VERSION ""

NS_ :

	ENVs_

BS_:

BU_: OVMS BMS ESP Gateway BCM ChargeCtrl ClimaECU Instruments AmbientSensor GearModule Powertrain Motor

// ---------------------------------------------------------------------------
// KCAN (500 kbps) — convenience/comfort bus, accessible via J533 harness
// OVMS: CAN bus 3 (m_can3).  Most metric data lives here.
// ---------------------------------------------------------------------------

BO_ 253 ESP_Speed: 8 ESP
 SG_ Speed : 32|16@1+ (0.01,0) [0|655.35] "km/h" OVMS

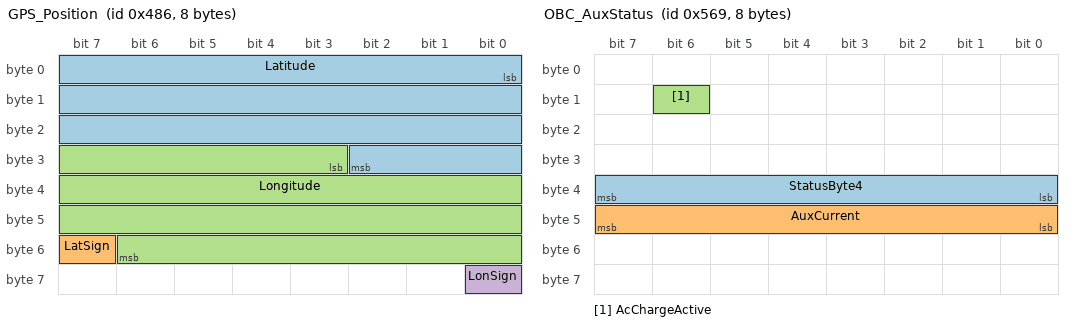
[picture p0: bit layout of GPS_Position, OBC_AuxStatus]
BO_ 1158 GPS_Position: 8 Gateway
 SG_ Latitude : 0|27@1+ (1e-006,0) [0|90] "deg" OVMS
 SG_ LatSign : 55|1@1+ (1,0) [0|1] "" OVMS
 SG_ Longitude : 27|28@1+ (1e-006,0) [0|180] "deg" OVMS
 SG_ LonSign : 56|1@1+ (1,0) [0|1] "" OVMS

BO_ 1385 OBC_AuxStatus: 8 OBC
 SG_ StatusByte4 : 32|8@1+ (1,0) [0|255] ""  Vector__XXX
 SG_ AuxCurrent  : 40|8@1+ (1,0) [0|255] "A" Vector__XXX
 SG_ AcChargeActive : 14|1@1+ (1,0) [0|1] "" Vector__XXX

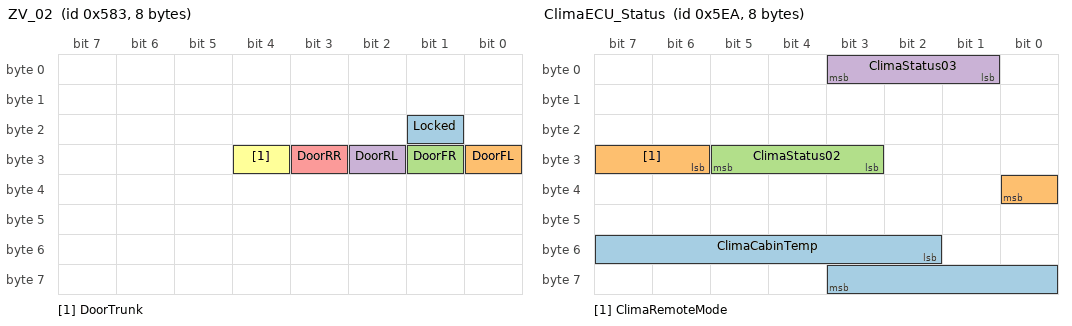
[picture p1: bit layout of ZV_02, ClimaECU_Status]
BO_ 1411 ZV_02: 8 BCM
 SG_ Locked : 17|1@1+ (1,0) [0|1] "" OVMS
 SG_ DoorFL : 24|1@1+ (1,0) [0|1] "" OVMS
 SG_ DoorFR : 25|1@1+ (1,0) [0|1] "" OVMS
 SG_ DoorRL : 26|1@1+ (1,0) [0|1] "" OVMS
 SG_ DoorRR : 27|1@1+ (1,0) [0|1] "" OVMS
 SG_ DoorTrunk : 28|1@1+ (1,0) [0|1] "" OVMS

BO_ 1428 ChargeManagement: 8 ChargeCtrl
 SG_ ChargeDurationFull : 12|9@1+ (5,0) [0|2555] "min" OVMS
 SG_ ChargeTimerMode : 21|2@1+ (1,0) [0|3] "" OVMS
 SG_ ChargeInProgress : 29|1@1+ (1,0) [0|1] "" OVMS
 SG_ ChargeType : 42|2@1+ (1,0) [0|3] "" OVMS
 SG_ ChargePort : 42|2@1+ (1,0) [0|3] "" OVMS
 SG_ CabinSetpoint : 56|5@1+ (0.5,15.5) [15.5|31.5] "degC" OVMS

BO_ 1438 BMS_BatTemp: 8 BMS
 SG_ BatTemp : 16|8@1+ (0.5,-40) [-40|87.5] "degC" OVMS

BO_ 1482 BMS_BatEnergyRemaining: 8 BMS
 SG_ BatEnergyRemaining : 12|11@1+ (0.05,0) [0|102.35] "kWh" OVMS

BO_ 1514 ClimaECU_Status: 8 ClimaECU
 SG_ ClimaCabinTemp : 50|10@1+ (0.1,-40) [-40|62.3] "degC" OVMS
 SG_ ClimaRemoteMode : 30|3@1+ (1,0) [0|7] "" OVMS
 SG_ ClimaStatus02 : 27|3@1+ (1,0) [0|7] "" OVMS
 SG_ ClimaStatus03 : 1|3@1+ (1,0) [0|7] "" OVMS

BO_ 949 ClimaRunning_3B5: 8 ClimaECU
 SG_ ClimaRunning : 7|1@1+ (1,0) [0|1] "" OVMS

BO_ 1516 ClimaStatus_5EC: 8 ClimaECU
 SG_ ClimaStatus : 40|8@1+ (1,0) [0|255] "" OVMS

BO_ 1525 Instruments_Range: 8 Instruments
 SG_ RangeEst : 29|11@1+ (1,0) [0|2047] "km" OVMS
 SG_ RangeIdeal : 0|11@1+ (1,0) [0|2047] "km" OVMS

BO_ 1626 BCM_01: 8 BCM
 SG_ HoodOpen : 32|1@1+ (1,0) [0|1] "" OVMS

BO_ 1646 InnenTemp: 8 BCM
 SG_ CabinTemp : 32|8@1+ (0.5,-50) [-50|77] "degC" OVMS
 SG_ ClimaRunning : 17|1@1+ (1,0) [0|1] "" OVMS

BO_ 1712 FS_Temp: 8 AmbientSensor
 SG_ FsTemp : 32|8@1+ (0.5,-40) [-40|87.5] "degC" OVMS

BO_ 1717 AmbientTemp: 8 AmbientSensor
 SG_ AirTemp : 16|10@1+ (0.1,-40) [-40|62.3] "degC" OVMS
 SG_ SolarTemp : 48|11@1+ (0.1,-40) [-40|164.7] "degC" OVMS

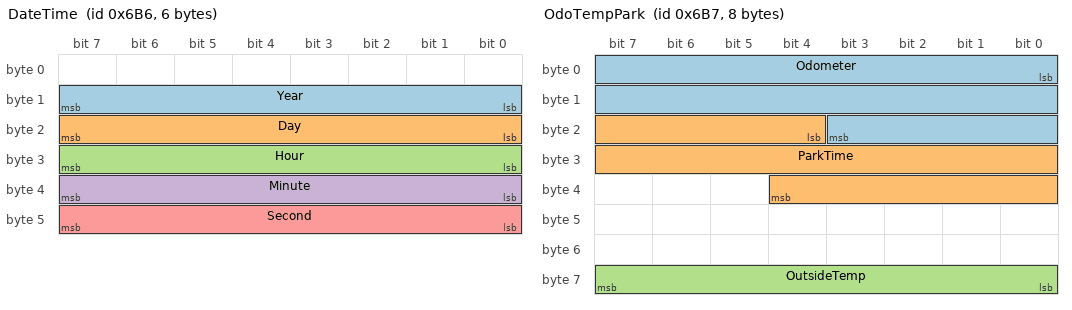
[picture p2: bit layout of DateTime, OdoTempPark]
BO_ 1718 DateTime: 6 Gateway
 SG_ Year : 8|8@1+ (1,0) [0|99] "" OVMS
 SG_ Day : 16|8@1+ (1,0) [1|31] "" OVMS
 SG_ Hour : 24|8@1+ (1,0) [0|23] "" OVMS
 SG_ Minute : 32|8@1+ (1,0) [0|59] "" OVMS
 SG_ Second : 40|8@1+ (1,0) [0|59] "" OVMS

BO_ 1719 OdoTempPark: 8 Gateway
 SG_ Odometer : 0|20@1+ (1,0) [0|1048575] "km" OVMS
 SG_ ParkTime : 20|17@1+ (1,0) [0|131071] "s" OVMS
 SG_ OutsideTemp : 56|8@1+ (0.5,-50) [-50|77] "degC" OVMS

// OVMS transmits this frame on KCAN as the OCU application-level presence frame.
// Must be sent at ~5 Hz while active. Action bits are set for one tick then cleared.
// Note: this is NOT the OSEK NM alive — see 0x1B00007D below for OVMS's NM alive
// (0x1B000067 is a foreign ECU's node, not ours — see comment there).
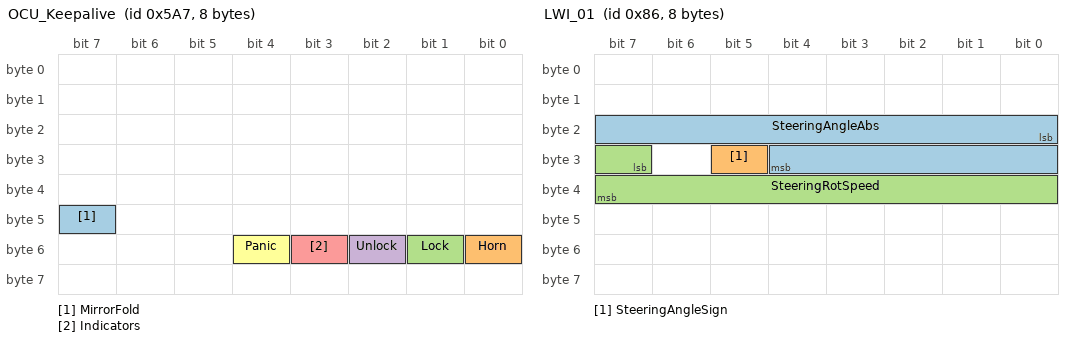
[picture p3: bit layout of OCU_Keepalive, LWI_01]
BO_ 1447 OCU_Keepalive: 8 OVMS
 SG_ MirrorFold : 47|1@1+ (1,0) [0|1] "" Vector__XXX
 SG_ Horn : 48|1@1+ (1,0) [0|1] "" Vector__XXX
 SG_ Lock : 49|1@1+ (1,0) [0|1] "" Vector__XXX
 SG_ Unlock : 50|1@1+ (1,0) [0|1] "" Vector__XXX
 SG_ Indicators : 51|1@1+ (1,0) [0|1] "" Vector__XXX
 SG_ Panic : 52|1@1+ (1,0) [0|1] "" Vector__XXX

// ---------------------------------------------------------------------------
// FCAN (500 kbps) — powertrain bus, accessible via J533 harness
// OVMS: CAN bus 2 (m_can2).  BMS (SoC, HV bus, trip energy), gear selector, VIN.
// ---------------------------------------------------------------------------

BO_ 305 BMS_SoC: 8 BMS
 SG_ SoC : 24|8@1+ (0.5,0) [0|127.5] "%" OVMS

BO_ 401 BMS_PowerBus: 8 BMS
 SG_ BatCurrent : 12|12@1+ (1,-2047) [-2047|2048] "A" OVMS
 SG_ BatVoltage : 24|12@1+ (0.25,0) [0|1023.75] "V" OVMS

BO_ 687 BMS_TripEnergy: 8 BMS
 SG_ NetEnergy : 16|16@1+ (1,0) [0|65535] "mWh" OVMS

BO_ 391 GearSelector: 8 GearModule
 SG_ GearPosition : 16|4@1+ (1,0) [0|15] "" OVMS

// VIN is spread across three sequential frames (frame index 0, 1, 2 in d[0]).
// Not representable as a simple signal; assembled in firmware from all three.
BO_ 1716 VIN_Broadcast: 8 Gateway
 SG_ VIN_FrameIndex : 0|8@1+ (1,0) [0|2] "" OVMS

// Clamp/terminal status (0x3C0). d[2] carries the terminal bits: KL_S (accessory)
// and KL_15 (ignition). KL_15 = car awake / switched on by the user -> ms_v_env_awake.
BO_ 960 ClampStatus: 8 Gateway
 SG_ KlS_Accessory : 16|1@1+ (1,0) [0|1] "" OVMS
 SG_ Kl15_Ignition : 17|1@1+ (1,0) [0|1] "" OVMS

// OBD_01 (0x391). d[7] bit 5 = OBD_Driving_Cycle: the drivetrain READY flag, set only
// when the car is drivable. ms_v_env_on = KL_15 && READY. d[5] = accelerator pedal.
BO_ 913 OBD_01: 8 Powertrain
 SG_ OBD_Driving_Cycle : 61|1@1+ (1,0) [0|1] "" OVMS
 SG_ OBD_Abs_Pedal_Pos : 40|8@1+ (0.392,0) [0|100] "%" OVMS

// ---------------------------------------------------------------------------
// FCAN decode candidates and partially decoded frames.
// Originally observed in can2-3.3.005-800-gc60d79ed-dirty_ota_1_edge-20260412-175611
// (CCS charging, ignition off). Per-frame comments record progress as stimulation
// captures land. As of Capture 17 (D + B short drive): 0x0B2 fully decoded as
// wheel speeds; 0x057 byte 3 and 0x0B4 bytes 3/6 partially decoded.
// ---------------------------------------------------------------------------

BO_ 87 Unknown_057: 4 Vector__XXX
 SG_ MotorTorqueRequest : 24|8@1+ (1,0) [0|255] "" OVMS
BO_ 134 LWI_01: 8 Gateway
 SG_ SteeringAngleAbs : 16|13@1+ (0.1,0) [0|800] "deg" OVMS
 SG_ SteeringAngleSign : 29|1@1+ (1,0) [0|1] "" OVMS
 SG_ SteeringRotSpeed : 31|9@1+ (5,0) [0|2500] "deg/s" OVMS
BO_ 167 Motor_11: 8 Motor
BO_ 168 Motor_12: 8 Motor
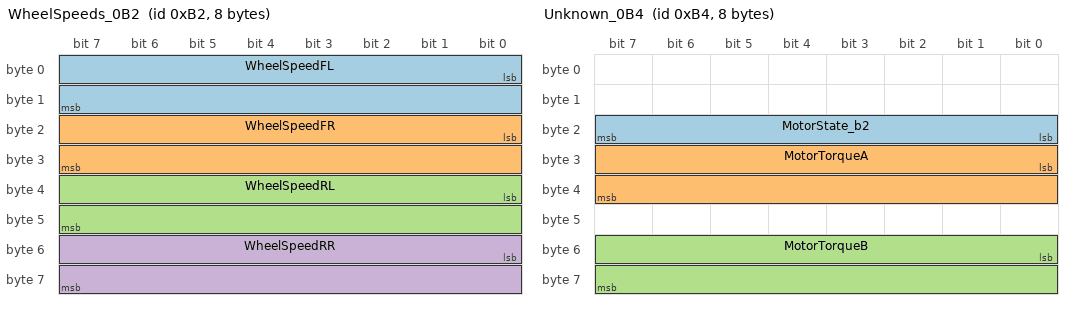
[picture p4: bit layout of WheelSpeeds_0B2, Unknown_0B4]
BO_ 178 WheelSpeeds_0B2: 8 ESP
 SG_ WheelSpeedFL : 0|16@1+ (0.0078125,0) [0|511.99] "km/h" OVMS
 SG_ WheelSpeedFR : 16|16@1+ (0.0078125,0) [0|511.99] "km/h" OVMS
 SG_ WheelSpeedRL : 32|16@1+ (0.0078125,0) [0|511.99] "km/h" OVMS
 SG_ WheelSpeedRR : 48|16@1+ (0.0078125,0) [0|511.99] "km/h" OVMS
BO_ 179 Unknown_0B3: 8 Vector__XXX
BO_ 180 Unknown_0B4: 8 Vector__XXX
 SG_ MotorState_b2 : 16|8@1+ (1,0) [0|255] "" OVMS
 SG_ MotorTorqueA : 24|16@1+ (1,0) [0|65535] "" OVMS
 SG_ MotorTorqueB : 48|16@1+ (1,0) [0|65535] "" OVMS
BO_ 263 Motor_04: 8 Motor
BO_ 288 TSK_06: 8 Motor
BO_ 289 Motor_20: 8 Motor
BO_ 869 BrakePedal_365: 8 Vector__XXX
 SG_ BrakeActive : 32|1@1+ (1,0) [0|1] "" OVMS
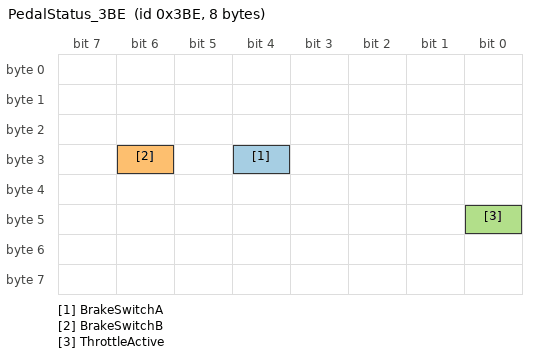
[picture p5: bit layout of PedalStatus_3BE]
BO_ 958 PedalStatus_3BE: 8 Vector__XXX
 SG_ BrakeSwitchA : 28|1@1+ (1,0) [0|1] "" OVMS
 SG_ BrakeSwitchB : 30|1@1+ (1,0) [0|1] "" OVMS
 SG_ ThrottleActive : 40|1@1+ (1,0) [0|1] "" OVMS

// ---------------------------------------------------------------------------
// OSEK/AUTOSAR NM frames on KCAN (29-bit extended IDs: 0x1B000000 | node_id)
// Each active KCAN node broadcasts its alive frame at ~1 Hz.
//
// Shared 8-byte payload layout, confirmed across 10 nodes (9 real ECUs plus
// OVMS: 0x0C, 0x0E, 0x10, 0x14, 0x46, 0x4A, 0x4B, 0x67, 0xA9, 0x7D) in
// tests/candumps/can3-3.3.006-364-gaefeffec5_ota_0_edge-20260731-112417.crtd
// (14384 frames, 29.3s of bus traffic, RX unless noted). byte0 matches the
// low byte of the CAN ID without exception on every one of the 10 nodes.
//
//   byte0  node id (== CAN ID & 0xFF).
//   byte1  control. Real nodes: 0x00 (92% of frames), 0x10 (8%) — and 0x10 is
//          seen ONLY on node 0x67. CONSISTENT WITH an Active-Wakeup/initiator
//          bit in an AUTOSAR-style NM control bit vector (0x67 is the node
//          this firmware previously impersonated, see BO_ 2600468583 below),
//          but that reading rests on one capture and is not proven against
//          the MQB NM spec.
//   byte2  state. Real nodes: 0x01 (74%), 0x02 (25%), 0x04 (1%). Bus-wide
//          transition observed: nodes 0x0C, 0x14 and 0x0E each flip
//          0x01 -> 0x02 at the same instant (t=+5.33s in the capture above),
//          independently of one another. CONSISTENT WITH Repeat-Message ->
//          Normal-Operation (present in both OSEK NM and AUTOSAR NM) a few
//          seconds after wake — a hypothesis from one 29s capture, NOT
//          settled against the spec.
//   byte3  real nodes: 0x01 (92%) / 0x00 (8%).
//   byte4  real nodes: 0x04 (89%) / 0x0c (11%) / 0x00 (1%). Node 0x0E visits
//          byte2=0x04 with byte4=0x00 together — CONSISTENT WITH a
//          ready-to-sleep state, same one-capture caveat as byte2 above.
//   byte5  real nodes: 0x00 (98%) / 0x08 (2%).
//   byte6  real nodes: 0x00 (82%) / 0x04 (9%) / 0x1e (9%).
//   byte7  0x00 on 100% of real-node frames (invariant).
//
// OVMS (node 0x7D, BO_ 2600468605 below) holds byte2=0x08 and byte4=0x14
// constant across all 30 transmitted frames in the capture and never
// transitions — outside this one capture's real-node byte2/byte4 sets above,
// but NOT unattested corpus-wide: a full-corpus scan (all 42 .crtd, RX only,
// 73510 NM frames, 16 nodes) finds byte2=0x08 as the second most common
// byte2 value (22234 frames, 14 real nodes) and byte4=0x14 directly attested
// (126 frames, nodes 0x0E and 0x10) — both were deliberately chosen in
// WI-NM-1 from that full-corpus scan (see vehicle_vwegolf.h). The open
// question is state-machine participation over time (byte2 is a state field
// that real nodes vary and we hold constant), not value legitimacy.
//
// OVMS must send 0x1B00007D before issuing BAP commands on a freshly-woken bus.
// The clima ECU rejects BAP from nodes not present in the NM ring.
// ---------------------------------------------------------------------------

// 0x1B000067 (extended) — foreign ECU's OSEK NM alive, node 0x67. NOT ours: a
// corpus scan (crtd.py iter_frames, RX only, over all 41 .crtd files in
// tests/candumps/, filtered to id 0x1B0000xx) found 73264 NM frames total across
// 32 of the 41 files; node 0x67 already occupied by a live ECU — 20 of those files
// carry 0x1B000067, 6369 frames at sustained cadence, payload varying
// within a session (67 10 04 01 01 / 67 10 08 01 01 / 67 00 08 01 01 — byte1=0x00
// is never something OVMS emits). The formerly-"confirmed" fixed payload
// 67 10 41 84 14 00 00 00, previously attributed to OVMS, appears zero times in
// that scan — sender attribution below corrected accordingly. See VWEGOLF_NM_NODE_ID
// in vehicle_vwegolf.h.
BO_ 2600468583 NM_Unknown67_Alive: 8 Vector__XXX
 SG_ NM_NodeId : 0|8@1+ (1,0) [0|255] "" Vector__XXX
 SG_ NM_Control : 8|8@1+ (1,0) [0|255] "" Vector__XXX

// 0x1B00007D (extended) — OVMS OSEK NM alive (node 0x7D = OVMS).
// Sent by CommandWakeup() and SendNmAlive() on/after a freshly-woken bus, before
// issuing BAP commands. 0x7D is unobserved across all 73264 scanned NM frames —
// chosen because it is unclaimed IN THE CAPTURES, not because the slot is confirmed
// free on the vehicle. Payload 7D 10 08 01 14 00 00 00: byte2/byte3 mirror the
// single-bit PNC-request pattern node 0x46 (Climatronic) puts on the wire.
// can3-3.3.006-364-gaefeffec5_ota_0_edge-20260731-112417.crtd corroborates
// byte1=0x10 as an Active-Wakeup/initiator-style control bit (see the shared
// payload layout comment above) — one capture, not proven. OSEK-vs-AUTOSAR
// identification of the NM variant itself remains unsettled against the MQB
// NM spec.
// See VWEGOLF_NM_PAYLOAD in vehicle_vwegolf.h.
BO_ 2600468605 NM_OVMS_Alive: 8 OVMS
 SG_ NM_NodeId : 0|8@1+ (1,0) [0|255] "" Vector__XXX
 SG_ NM_Control : 8|8@1+ (1,0) [0|255] "" Vector__XXX

// 0x1B000025 (extended) — ClimaECU OSEK NM alive (node 0x25), expected by
// protocol convention (mirrors the node-claim pattern of 0x1B000067/0x1B00007D
// above) — NOT confirmed on the wire. Zero occurrences across all 42 .crtd
// files in the corpus (RX and TX). See CM_ below for the full node-observation
// breakdown.
BO_ 2600468517 NM_ClimaECU_Alive: 8 ClimaECU
 SG_ NM_NodeId : 0|8@1+ (1,0) [0|255] "" Vector__XXX
 SG_ NM_Control : 8|8@1+ (1,0) [0|255] "" Vector__XXX

// 0x17330301 (extended) — dominant-bit wake frame sent by CommandWakeup().
// TX_Fail is expected (nodes sleeping, no ACK). Dominant bits wake transceivers.
// Data: 40 00 01 1F 00 00 00 00  (confirmed from kcan-can3-clima_control.crtd)
// Response on 0x17330E10 when bus is live. Full BAP decode pending.
BO_ 2536702721 WakeFrame_17330301: 8 OVMS
 SG_ WF_Byte0 : 0|8@1+ (1,0) [0|255] "" Vector__XXX

// ---------------------------------------------------------------------------
// BAP extended frames on KCAN (29-bit IDs, node 0x25 = clima ECU)
// These are multi-frame BAP messages, not conventional CAN signals.
// See docs/vw-bap-protocol.md and docs/clima-control-bap.md for protocol details.
// CAN ID in DBC = raw_id | 0x80000000 to flag as extended frame.
// ---------------------------------------------------------------------------

// 0x17330110 (extended) — J533 Gateway → bus BAP status broadcast, node 0x01.
// Port 0x1B (driver zone) and port 0x21 (passenger zone) carry the real-time clima setpoint
// as a LE uint16: raw = (setpoint_C - 10.0) * 10. Confirmed Capture 2 (kcan-can3-clima_range).
// Multi-frame BAP — not a conventional signal. See clima-control-bap.md.
BO_ 2536702224 BAP_GatewayStatus: 8 Gateway
 SG_ BAP_FrameType : 0|8@1+ (1,0) [0|255] "" OVMS

// 0x17332501 (extended) — OVMS → ClimaECU BAP command channel
// Carries: BAP Get wake ping (2 bytes), and the 3-frame start/stop sequence.
// See clima-control-bap.md for complete frame content documentation.
BO_ 2536711425 BAP_ClimaCmd: 8 OVMS
 SG_ BAP_FrameType : 0|8@1+ (1,0) [0|255] "" ClimaECU

// 0x17332510 (extended) — ClimaECU → OVMS BAP status/ACK channel
// ECU echoes our BAP counter (| 0x80) to confirm receipt, then broadcasts
// periodic state on ports 0x19 and 0x1a.
// Port 0x18 (49 58 XX): transactional ACK, NOT a run-state. It emits a spurious 49 58 00
// mid-session (capture all-168388a82-...-221008), so it does NOT drive ms_v_env_hvac — it
// is used only to stand down the OCU ring once a command is acknowledged. ms_v_env_hvac is
// driven by 0x3B5 ClimaRunning (+ command optimistic set + hold). The older "port 0x12
// primary source" understanding (Captures 6/12) was superseded. See clima-control-bap.md.
BO_ 2536711440 BAP_ClimaStatus: 8 ClimaECU
 SG_ BAP_FrameType : 0|8@1+ (1,0) [0|255] "" OVMS

// 0x1A5554A8 (extended) — OBC live-telemetry. Multiplexed by byte 0.
// Capture 14 (Type2 AC charge session, 20260413-121648) confirmed:
//   - Mux A (b0 upper nibble 0x6): `6X c9 aa 9c 83 b6 ed 0e` — static
//     payload across the session, header/identifier (not live telemetry).
//   - Mux B (b0 upper nibble 0x5): `5X 5d 00 80 <b4> c2 dc 69` — b4
//     increments +1 per second during active charging (Capture 14 observed
//     0x9e..0xb8 monotonic; prior capture saw 164..174 linear). Consistent
//     with a charge totalizer — exact unit (Wh? Ws×10? minutes?) still TBD,
//     needs a longer session with known energy delivery to calibrate.
//   - b0 bit 2 toggles every frame within each mux (rolling alive bit).
//   - Alive at ~2 Hz during charge; sleep sentinel `03 fe ff ff e7 ff ff ff`
//     when bus up and no charge; one-shot zeros frame during teardown.
//   - Active window brackets 0x594 charge-on: leads it by ~1.5 s, lingers
//     ~5 s into the `b1=c0` post-charge hold.
//   - Other Mux B bytes (b1, b2, b3, b5, b6, b7) were static this session —
//     candidate for instantaneous current/voltage/power but needs a higher
//     power session to confirm.
BO_ 2589283496 OBC_Telemetry_1A5554A8: 8 Vector__XXX
 SG_ MuxSelector M : 4|4@1+ (1,0) [0|15] "" OVMS
 SG_ AliveBit : 2|1@1+ (1,0) [0|1] "" OVMS
 SG_ ChargeTotalizer m5 : 32|8@1+ (1,0) [0|255] "" OVMS

// ---------------------------------------------------------------------------
// Comments (CM_)
// ---------------------------------------------------------------------------

CM_ BU_ OVMS "OVMS v3 module — acts as OCU (On-board Control Unit) node on KCAN";
CM_ BU_ BMS "High-voltage battery management system";
CM_ BU_ ESP "Electronic stability program — source of wheel-speed-derived vehicle speed";
CM_ BU_ Gateway "J533 CAN gateway — bridges FCAN and KCAN, aggregates GPS and odometer";
CM_ BU_ BCM "Body control module — doors, locks, hood, interior temperature sensor";
CM_ BU_ ChargeCtrl "Charge control / HV charge management ECU";
CM_ BU_ ClimaECU "Climatronic / Standklima ECU — remote pre-conditioning via BAP";
CM_ BU_ Instruments "Instrument cluster — range estimates derived from BMS model";
CM_ BU_ AmbientSensor "Ambient temperature sensor cluster (solar + outside air)";
CM_ BU_ GearModule "Gear selector module (Waehlhebel)";
CM_ BU_ Powertrain "Powertrain / motor controller — terminal status and OBD readiness broadcasts";

CM_ BO_ 949 "KCAN 0x3B5. PRIMARY ms_v_env_hvac run-state source. Byte[0] bit 7 = cabin actively conditioned (blower running), trigger-agnostic. High-rate (~8 Hz); tracks the blower duty cycle so it thermostat-cycles within a session — firmware applies a hold (VWEGOLF_HVAC_RUN_HOLD_SECS) to bridge the gaps and clear on sleep. Confirmed Captures 1, 2, firmware start/stop (20260407-141135), and all-168388a82-...-224827.";
CM_ BO_ 1516 "KCAN. Secondary clima status byte from clima ECU. Observed 0x04=idle, 0x07=active. Full decode not confirmed.";
CM_ BO_ 2536702224 "KCAN (extended 29-bit ID 0x17330110). J533 gateway BAP status broadcast, node 0x01. Port 0x1B carries real-time driver-zone setpoint; port 0x21 mirrors it for passenger zone. Encoding: raw = (celsius - 10) * 10, LE uint16. Confirmed Captures 2, 7 (18C=0x50, 22C=0x78). Multi-frame BAP — see clima-control-bap.md.";
CM_ BO_ 253 "KCAN. Vehicle speed from ESP. Confirmed from captures.";
CM_ BO_ 305 "FCAN. State of charge from BMS. Confirmed. 0xFE is a startup sentinel (127.0%) — discard.";
CM_ BO_ 401 "FCAN. HV bus current and voltage from BMS. Confirmed from captures.";
CM_ BO_ 687 "FCAN. Net trip energy counter. Originally hypothesised as separate EnergyRecd/EnergyUsed at b4/b5 + b6/b7 (pre-2026 RE notes); on this vehicle bytes 4-7 are static zero across an entire driving session (cap 20260503-143106) and bytes 2-3 carry a single 16-bit LE counter that resets to 0 on key-on, climbs during draw, decrements during regen, and wraps mod 65536. Hypothesis: mWh net cumulative — pre-park value 58496 + 26 wraparounds ≈ 1762 Wh vs 0x191 power-integral net consumption 1706 Wh (within ~3 %). Mid-trip 20 s-sampled dips consistent with rapid wraparound at high power (e.g. -100 kW = wrap every ~0.6 s). Needs single-bus FCAN drive + parallel power-integral capture to verify mWh scale and regen-sign behaviour.";
CM_ BO_ 1158 "KCAN. GPS position. Encoding inferred from RE. Sign bits for S/W hemisphere not yet decoded — positive values only.";
CM_ BO_ 1385 "KCAN. OBC auxiliary/DC-DC status — NOT the AC charge inlet. Originally decoded as AC line voltage + charge current, but capture review disproved it: byte 4 is constant 0xF8 in every state (parked+clima, idle, AC, CCS DC) and byte 5 is a DC-DC/aux current (0 idle, ~9 A clima-while-parked, ~13 A through a 33 kW CCS DC session). byte4*byte5 is a flat ~3.2 kW during a 33 kW charge — does not track charge rate. Charge voltage/current/power are derived from the BMS pack UDS poll instead. No OVMS metric is driven from this frame. Caps: all-dc583be4a-…-132333 (CCS DC), all-168388a82 (idle), kcan-can3-clima_control (parked clima). opendbc vw_mqb.dbc names 0x569 HVEM_04 (HV-Energiemanagement, no signal defs) — independently supports the energy-management (not AC inlet) reading.";
CM_ SG_ 1385 StatusByte4 "Byte 4. Constant 0xF8 across all observed states — status/flag byte, not a voltage. The earlier '248 V mains' reading was a coincidental match of 0xF8.";
CM_ SG_ 1385 AuxCurrent "Byte 5. Auxiliary/DC-DC-converter current, 1 A/bit: 0 idle, ~9 A clima-while-parked, ~13 A during CCS DC charge. Tracks the 12 V/DC-DC load, not the HV charge current.";
CM_ SG_ 1385 AcChargeActive "Byte 1 bit 6. 0x40 set during sustained charging; d[1]=0xf0 also observed (early CP negotiation). Not used as a metric gate — charge_inprogress (0x594) is authoritative.";
CM_ BO_ 1411 "KCAN. ZV_02 central locking and door open status. Confirmed from captures.";
CM_ BO_ 1428 "KCAN. HV charge management: duration, timer, plug type, charge state, chargeport, cabin setpoint. ChargeType/ChargePort share same bits — ChargePort derived from non-zero ChargeType. Confirmed from AC Type 2 charge cycle (20260407-131402) and 100% SOC idle (20260407-141135). ChargeType=2 (DC_CCS) confirmed during CCS DC charge (20260712-124542): KCAN wakes briefly at plug-in and charge-stop, silent mid-charge, ChargeType=2 visible t=213.6..278.6. NOTE: ChargeType/ChargePort bit overlap makes cantools message decode raise DecodeError — decode this frame from raw bytes (bits 42-43).";
CM_ BO_ 1438 "KCAN. HV battery pack temperature from BMS. Confirmed from captures.";
CM_ BO_ 1482 "KCAN. HV battery REMAINING energy content (tracks SoC; 5 kWh observed at 18% SoC 2026-07-10). NOT pack capacity — earlier BatCapacity name was wrong. Encoding inferred; values plausible.";
CM_ BO_ 1514 "KCAN 0x5EA. Clima ECU broadcast status (StandklimaStatus_02). ClimaRemoteMode here = 'ECU energized' (ignition/ACC or remote session), NOT cabin conditioning — do not use for ms_v_env_hvac (it pins/couples to ignition; capture all-168388a82-...-224827). Run-state is 0x3B5 ClimaRunning. ClimaCabinTemp here is the PRIMARY ms_v_env_cabintemp source (WI-cabintemp-1, 2026-07-16): 0x066E InnenTemp d[4] is permanently 0xFE ('not ready') on this car, disproven across all 22 captures on record.";
CM_ BO_ 1525 "KCAN. Range estimates from instrument cluster. RangeIdeal is an 11-bit field (bits 0-10), not 8 — byte[1] bits 11-15 (the top 5 bits of the would-be ClimaIdle byte) are never set in any of 2959 frames across 33 captures. Sentinel frame `FE 07 F8 DF FF FF C7 FF` puts RangeIdeal AND RangeEst at the 11-bit invalid value 0x7FE simultaneously, byte-identical across 4 captures: 20260524-221008 t=153.7, 20260422-173035 t=0.4 (also kcan-can3-clima_inject t=0.4, kcan-can3-clima_schedule t=116.4). The physical invariant RangeIdeal >= RangeEst holds on all 2933 non-sentinel frames under the 11-bit read; the former 8-bit ClimaIdle read at 8|8 violated it on 69 frames (byte[1]==0x01) by up to 254 km. DISPROVEN: a former SG_ ClimaIdle at 8|8 (0x00=active, 0x01=idle) was a misread of this same carry bit — clima-on cuts ~18-22 km of reserve, dropping RangeIdeal from 264 to 242-246 km, crossing the 256 boundary and clearing bit 8; this correlated with 0x3B5 ClimaRunning transitions in exactly one capture (clima-sequence.crtd) and in none of three others. Use 0x3B5 ClimaRunning (BO_ 949) for clima run-state instead. Bits 53-63 carry an 11-bit mirror of RangeEst (equal in 2939/2939 frames observed) — undecoded, no signal added.";
CM_ BO_ 1626 "KCAN. BCM_01 bonnet/hood open indicator. Confirmed from captures.";
CM_ BO_ 1646 "KCAN. Interior cabin temperature sensor (InnenTemp). Log-only (WI-cabintemp-1, 2026-07-16): d[4] is permanently 0xFE ('not ready' sentinel, decodes to 77 degC) on this car — disproven across all 22 captures on record, never observed non-sentinel. ms_v_env_cabintemp now sourced from 0x5EA ClimaCabinTemp. Byte[2] bit 1 also carries primary clima running flag.";
CM_ BO_ 1712 "KCAN. Windshield/front area temperature sensor. Logged but not yet mapped to a standard metric.";
CM_ BO_ 1717 "KCAN. Dual ambient temperature sensors: outside air and solar. Encoding inferred.";
CM_ BO_ 1718 "KCAN. Gateway date/time broadcast at 1 Hz. Year = last 2 digits of year (26 = 2026). Day = day-of-month. Hour/Minute/Second = wall-clock time. d[0]=0x4B static across captures — possibly encodes month (both confirmed captures are April); needs capture in a different month to confirm. Confirmed from cap14 (20260413) and cap8 (20260428): day and hour/min/sec match file timestamps.";
CM_ BO_ 1719 "KCAN. Odometer, park time, and filtered outside temperature. Odometer and outside temp confirmed. Park time encoding not fully confirmed — bit layout inferred from firmware.";
CM_ BO_ 1447 "KCAN TX by OVMS. OCU OSEK NM keepalive. All-zeros = idle. Action bits are one-shot: set for one transmission then cleared. Lock/unlock bits require additional auth bytes not yet captured.";
CM_ BO_ 2600468583 "KCAN RX, foreign ECU (extended 29-bit ID 0x1B000067). OSEK NM alive for node 0x67 — NOT OVMS. Corpus scan (crtd.py iter_frames, RX only, 41 .crtd files in tests/candumps/, id filter 0x1B0000xx) found 73264 NM frames total across 32 of the 41 files; node 0x67 present in 20 of those files (6369 frames, sustained cadence); payload varies within a session (67 10 04 01 01 / 67 10 08 01 01 / 67 00 08 01 01 — byte1=0x00 never appears in anything OVMS emits). The former 'confirmed' payload 67 10 41 84 14 00 00 00, previously attributed to OVMS, appears zero times in the scan — genuine duplicate-node collision, not our frame. OVMS's own NM alive is 0x1B00007D (BO_ 2600468605).";
CM_ BO_ 2600468605 "KCAN TX by OVMS (extended 29-bit ID 0x1B00007D). OSEK NM alive for OVMS node 0x7D. Must be sent before BAP commands on a freshly-woken bus — clima ECU rejects BAP from nodes absent from the NM ring. 0x7D chosen as unobserved across the 73264-frame NM corpus scan (not a confirmed-free allocation on the vehicle). Sent by CommandWakeup() and SendNmAlive(). Node 0x67 (BO_ 2600468583) was the prior choice, disproven as a foreign-ECU collision.";
CM_ BO_ 2600468517 "Extended 29-bit ID 0x1B000025. Expected to be OSEK NM alive for clima ECU node 0x25, by analogy with the observed NM node-claim pattern (0x1B0000xx) — this is a protocol-derived expectation, NOT an on-wire confirmation. Corpus scan (crtd.py, all 42 .crtd files in tests/candumps/, RX and TX) found zero occurrences of this frame. NM nodes actually observed on KCAN: 0C 0E 10 14 46 4A 4B 67 A9 received; 67 and 7D transmitted by OVMS (see BO_ 2600468583/2600468605). Node 0x25 is absent from all of them. Absence from this corpus is not proof the frame does not exist on the vehicle — it may simply be unrepresented in the captures on hand. Treat clima-ECU NM-alive as unverified until a capture shows it.";
CM_ BO_ 2536702721 "KCAN TX by OVMS (extended 29-bit ID 0x17330301). Dominant-bit wake frame sent as first frame in CommandWakeup(). TX_Fail expected when bus sleeping — dominant bits wake transceivers regardless. Response on 0x17330E10 when bus is live. Full BAP decode pending.";
CM_ BO_ 391 "FCAN. Gear selector position. Confirmed from captures. Corroborated by opendbc vw_mqb.dbc Motor_EV_01: MO_Waehlpos same bit position, identical enum (2=P 3=R 4=N 5=D 6=D/B). opendbc extras checked on drive cap 20260503-143106: MO_Drehzahl_VM (32|16) zero throughout — combustion-engine field, unused on BEV; EV_Rekuperationsstufe (12|3, 1-3 = D-mode reku paddle stages B1-B3) zero throughout all-B-mode drive — candidate, needs a D-mode drive with paddle taps; MO_HVEM_MaxLeistung (55|9 x50 W) reads 0/24000/25400 W — meaning unclear, unvalidated.";
CM_ BO_ 1716 "FCAN. VIN broadcast across three frames (frame index 0/1/2 in byte 0). Assembled in firmware from all three before committing.";
CM_ BO_ 87 "FCAN. DLC 4. Bytes 0/1 are a rolling counter. Byte 3 confirmed as accelerator-driven motor torque request from Capture 17 (D + B drive). Identical ramp in D and B captures (so not regen-related). Max ~0x26 at peak accel. Byte 2 also motion-correlated, role unclear. 1889 frames / 67 s (~28 Hz) in 20260412-175611 charging idle.";
CM_ SG_ 87 MotorTorqueRequest "Byte 3. Accelerator pedal / motor torque request. 0 at rest, ramps with throttle, plateaus during cruise, 0 again on lift-off (regardless of brake or regen). Confirmed Capture 17 (D + B drive). Max observed 0x26.";
CM_ BO_ 134 "FCAN. Steering wheel angle sensor (Lenkwinkel). Name + layout from opendbc vw_mqb.dbc LWI_01. Stationary-consistent in 20260412-175611 (static 5.1 deg) and 20260611-195720 (10.1 deg with 0.1-deg jitter + rotation-speed blips on wheel touch). Dynamic scale/sign confirmation pending unfiltered drive capture.";
CM_ SG_ 134 SteeringAngleAbs "Absolute steering angle, 0.1 deg/bit. Sign in SteeringAngleSign (opendbc: LWI_VZ_Lenkradwinkel). Direction convention unconfirmed.";
CM_ BO_ 167 "FCAN. Motor torque report per opendbc vw_mqb.dbc Motor_11 (MO_Mom_Ist_Summe 22|10 offset -509 Nm etc). NOT BMS as previously guessed. Stationary caps show 513 = VW SNA sentinel; signals not added until validated on unfiltered drive capture. Pair with 0xA8.";
CM_ BO_ 168 "FCAN. Motor torque limits + motor speed per opendbc vw_mqb.dbc Motor_12 (MO_Drehzahl_01 48|16 x0.25 rpm). Zero while stationary (consistent); signals pending unfiltered drive capture. Pair with 0xA7.";
CM_ BO_ 178 "FCAN. Four 16-bit LE wheel speeds at byte offsets 0/1, 2/3, 4/5, 6/7. Scale 1/128 km/h per bit (0.0078125). All-zeros while stationary. Confirmed Capture 17: cruise plateau lands at 30.05 km/h matching 30 kph driver target; all four wheels track within ±0.2 km/h. FCAN counterpart of KCAN ESP_Speed (0xFD). Either bus can source ms_v_pos_speed.";
CM_ SG_ 178 WheelSpeedFL "Front-left wheel speed. Scale 1/128 km/h per bit. Wheel position assignment (FL/FR/RL/RR) is by convention — exact mapping to physical wheels not yet confirmed. Capture 17.";
CM_ SG_ 178 WheelSpeedFR "Front-right wheel speed. See WheelSpeedFL note on position mapping.";
CM_ SG_ 178 WheelSpeedRL "Rear-left wheel speed. See WheelSpeedFL note on position mapping.";
CM_ SG_ 178 WheelSpeedRR "Rear-right wheel speed. See WheelSpeedFL note on position mapping.";
CM_ BO_ 179 "FCAN decode candidate. 1712 frames / 67 s (~26 Hz) in 20260412-175611.";
CM_ BO_ 180 "FCAN. Motor / inverter state frame. Bytes 0/1 are an unrelated rolling counter, present even at rest. Byte 5 always 0. Active bytes are b2, (b3,b4) as 16-bit LE pair, and (b6,b7) as 16-bit LE pair — fire during forward propulsion AND during regen. D-pedal-stop capture (17a) holds these at 0 because the powertrain is idling against held brake; B-mode captures (17b, 17c) light them up during all motion. Cap 17c (varied B drive 0-75 km/h) overturned the earlier Cap 17b hypothesis that b3 was a regen-active flag — it is the low byte of MotorTorqueA, which varies smoothly across drive and regen phases. Exact units, sign convention, and which pair is torque vs power vs current still TBD; needs UDS ground truth or another targeted capture.";
CM_ SG_ 180 MotorState_b2 "Byte 2. Small motion-correlated counter (0-25 observed). Wakes from 0 during motion, climbs slowly during regen, idles low during steady forward cruise, returns to 0 at standstill. Could be regen demand level / brake pedal request percent / inverter status counter — not yet identified. Independent from MotorTorqueA/B (can be non-zero with both at 0). Capture 17c.";
CM_ SG_ 180 MotorTorqueA "Bytes 3/4 as 16-bit LE pair. Continuous motor torque-like quantity active during both forward propulsion and regen. Cap 17c observations: steady ~53 during forward cruise at 56 km/h; ramps smoothly 53→600 during a 75→62 km/h regen brake; 642-653 during a brief cruise pulse on flat. Smooth ramp at regen release. Sign convention and units (Nm? %? raw torque counts?) not yet known — appears unsigned with regen events landing in the same numeric range as drive events. Promoted from earlier 'RegenStateFlag' single-byte hypothesis after Cap 17c showed b3 is the low byte of a pair, not a flag.";
CM_ SG_ 180 MotorTorqueB "Bytes 6/7 as 16-bit LE pair. Second motor quantity at a much larger numeric scale than MotorTorqueA. Cap 17c observations: 0 during steady forward cruise (MotorTorqueA=53 alone); ramps 848→5776 during the 75→62 km/h regen brake; 224-1216 during the cruise pulse. Decays to 0 smoothly at regen release. Likely torque-derived (power? current? requested vs actual?) but identity vs MotorTorqueA not yet resolved. Promoted from earlier 'RegenTorque' single-byte hypothesis after Cap 17c showed b6 is the low byte of a pair.";
CM_ BO_ 263 "FCAN. Name from opendbc vw_mqb.dbc Motor_04 (display RPM, oil pressure, fuel flow — combustion-centric; BEV repurposing unknown). Layout unvalidated.";
CM_ BO_ 288 "FCAN. Name from opendbc vw_mqb.dbc TSK_06 (cruise/ACC status, wheel brake torque). Layout unvalidated.";
CM_ BO_ 289 "FCAN. Name from opendbc vw_mqb.dbc Motor_20 (MO_Fahrpedalrohwert_01 12|8 x0.4 = accel pedal raw %). Pedal field 0 throughout stationary caps (consistent); signals pending unfiltered drive capture.";
CM_ BO_ 869 "FCAN. Bimodal frame observed in pedal stimulation capture 20260412-184855 (Capture 16). Byte 4 takes value 0x82 most of the time, 0x83 during brake application. 11 activations clustered in 13.7-25.4 s window. Hypothesis: brake torque/pressure request. Needs re-confirm with timestamped stimulation.";
CM_ BO_ 958 "FCAN. Multi-bit status frame with two distinct event windows in Capture 16 (20260412-184855). Stable = `00 00 e7 04 c0 a0 0c 00`. Byte 3 bits 4/6 set (0x54/0x44) co-fire with 0x365 brake activations and extend ~6 s past brake release — likely brake pedal switch / brake-light bits. Byte 5 bit 0 (a0→a1) fires in a later window 33.7-43.7 s — likely throttle pedal active. Needs re-confirm with timestamped stimulation.";
CM_ SG_ 869 BrakeActive "Byte 4 bit 0. 0 = idle, 1 = brake applied. Hypothesis from Capture 16 temporal cluster; not yet confirmed with timestamped stimulation.";
CM_ SG_ 958 BrakeSwitchA "Byte 3 bit 2 of `04/44/54` pattern — bit 4. Hypothesis: brake pedal switch. Co-fires with 0x365. Capture 16.";
CM_ SG_ 958 BrakeSwitchB "Byte 3 bit 6 of `04/44/54` pattern. Always co-occurs with bit 4 here. May be redundant switch or ABS-related. Capture 16.";
CM_ SG_ 958 ThrottleActive "Byte 5 bit 0. 0 = idle, 1 = accelerator pressed. Capture 16.";
CM_ BO_ 2536711425 "KCAN TX by OVMS (extended 29-bit ID 0x17332501). BAP command channel to clima ECU (node 0x25). Multi-frame BAP — not a conventional signal message. See clima-control-bap.md.";
CM_ BO_ 2536711440 "KCAN RX from clima ECU (extended 29-bit ID 0x17332510). BAP status/ACK channel. Port 0x18 (49 58 XX) is a transactional ACK, NOT a run-state — it emits a spurious 49 58 00 mid-session (capture all-168388a82-...-221008) so it does NOT drive ms_v_env_hvac; used only to stand down the OCU ring once a command is acknowledged (ECU echoes command counter | 0x80). ms_v_env_hvac run-state is 0x3B5 ClimaRunning. The earlier 'port 0x12 primary source' (Captures 6/7/12) was superseded. See clima-control-bap.md.";
CM_ BO_ 2589283496 "KCAN RX (extended 29-bit ID 0x1A5554A8). OBC live-telemetry, multiplexed by byte 0 upper nibble (0x5=telemetry mux, 0x6=static header). b0 bit 2 is a 0.5 Hz rolling alive bit inside each mux. Alive at ~2 Hz during charge, idle sentinel 03 FE FF FF E7 FF FF FF when bus up with no charge. Mux B byte 4 is a 1 Hz charge totalizer (unit TBD). Active window brackets 0x594 ChargeManagement with small lead/lag. Confirmed Capture 14 (AC Type 2, 20260413-121648). Needs longer session for b1/b2/b3/b5/b6/b7 decode.";
CM_ SG_ 2589283496 MuxSelector "Upper nibble of byte 0. 0x5 = telemetry mux (b4 carries charge totalizer). 0x6 = static header payload. Other values not observed.";
CM_ SG_ 2589283496 AliveBit "Byte 0 bit 2. Toggles every frame within each mux — rolling alive / sequence counter.";
CM_ SG_ 2589283496 ChargeTotalizer "Mux B byte 4. Increments +1 per second while 0x594 ChargeInProgress is true. Capture 14 observed 0x9e..0xb8 linear. Unit not yet calibrated (Wh? Ws×10? minutes? deciAh?).";

CM_ SG_ 949 ClimaRunning "Bit 7 of byte[0]. 1=cabin actively conditioned (blower running), any trigger. PRIMARY ms_v_env_hvac source (with hold). Confirmed Captures 1, 2, and all-168388a82-...-224827.";
CM_ SG_ 1516 ClimaStatus "Raw byte at byte[5]. Observed: 0x04=clima idle, 0x07=clima active. Intermediate values not yet decoded.";
CM_ SG_ 1646 ClimaRunning "Bit 1 of byte[2]. 0x38=off, 0x3A=on. NOT used — low-rate (~0.45 Hz) and unreliable: in capture all-168388a82-...-224827 it went off at t=43.8 and missed the later blower runs (t=58, 85) that 0x3B5 captured. Use 0x3B5 ClimaRunning (BO_ 949) for run-state. Confirmed Captures 1 and 2 only.";
CM_ SG_ 1719 ParkTime "17-bit field in d[2][7:4]:d[3]:d[4][4:0]. Encoding not fully confirmed — inferred from firmware bit extraction. Value in seconds (plausible against known parked snapshot).";
CM_ SG_ 305 SoC "Factor 0.5 %/LSB. Max valid raw = 0xFD (126.5%). Raw 0xFE is ECU startup sentinel — firmware discards it.";
CM_ SG_ 401 BatCurrent "Unsigned raw with offset: raw 2047 = 0 A. Positive = discharge, negative = charge (OVMS convention: power sign is negated).";
CM_ SG_ 687 NetEnergy "Bytes 2-3 LE 16-bit. Cumulative net energy since key-on, hypothesis 1 mWh per raw, modulo 65536. Resets to 0 on key-on, increments during draw, decrements during regen. Verified at trip-total scale (cap 20260503-143106): pre-park 58496 + 26 wraps ≈ 1762 Wh vs independent 0x191 integral 1706 Wh. Mid-trip dips on coarse 20 s sampling are aliased wraparounds. mWh scale and signed-wrap behaviour need single-bus FCAN re-capture to fully confirm.";
CM_ SG_ 1158 Latitude "Factor 1e-6 deg/LSB. Magnitude only (27 bits). Apply LatSign for hemisphere.";
CM_ SG_ 1158 LatSign "0=North, 1=South. Bit 55 (d[6] MSB). Inferred from bit layout; confirmed 0 for known N/E location. Needs S/W capture to fully verify.";
CM_ SG_ 1158 Longitude "Factor 1e-6 deg/LSB. Magnitude only (28 bits). Apply LonSign for hemisphere.";
CM_ SG_ 1158 LonSign "0=East, 1=West. Bit 56 (d[7] bit 0). Inferred from bit layout; confirmed 0 for known N/E location. Needs S/W capture to fully verify.";
CM_ SG_ 1411 Locked "1 = locked externally (ZV external lock signal).";
CM_ SG_ 1428 ChargeTimerMode "Raw value 1 = timer active. Other values = timer inactive.";
CM_ SG_ 1428 CabinSetpoint "Factor 0.5 degC/LSB, offset +15.5 degC. Range 15.5–31.5 degC.";
CM_ SG_ 1514 ClimaCabinTemp "Climatronic ECU cabin sensor. PRIMARY ms_v_env_cabintemp source (WI-cabintemp-1, 2026-07-16). Raw >= 1020 (>= 62.0 degC) is ECU 'not available' sentinel — firmware discards.";
CM_ SG_ 1514 ClimaRemoteMode "StandklimaRemoteModus. NOT used for ms_v_env_hvac — reflects 'clima ECU energized', not cabin conditioning: reads 1 whenever ignition/ACC (radio) is on OR a remote session keeps the ECU awake, and only drops to 0 when the ECU fully powers down. Capture all-168388a82-...-224827: pinned with ignition off, asserted by radio mode. Use 0x3B5 ClimaRunning for run-state instead. (Earlier 2=running/3=activating was a mis-RE.)";
CM_ SG_ 1514 ClimaStatus02 "StandklimaStatus field 2. Exact value meanings not yet decoded.";
CM_ SG_ 1514 ClimaStatus03 "StandklimaStatus field 3. Exact value meanings not yet decoded.";
CM_ SG_ 1646 CabinTemp "Factor 0.5 degC/LSB, offset -50 degC. Raw 0xFE is startup sentinel (decodes to 77 degC) — firmware discards it. Log-only (WI-cabintemp-1, 2026-07-16): permanently 0xFE on this car across all 22 captures on record — disproven as a metric source.";
CM_ SG_ 1447 Lock "TODO: lock command likely requires additional authentication bytes alongside this bit — not yet captured from OEM app.";
CM_ SG_ 1447 Unlock "TODO: unlock command likely requires additional authentication bytes — not yet captured.";
CM_ SG_ 391 GearPosition "Nibble values: 2=Park 3=Reverse 4=Neutral 5=Drive 6=B-mode. Other values undefined.";

// ---------------------------------------------------------------------------
// Value tables (VAL_)
// ---------------------------------------------------------------------------

VAL_ 949 ClimaRunning 0 "Off" 1 "On" ;
VAL_ 1516 ClimaStatus 4 "Idle" 7 "Active" ;
VAL_ 1646 ClimaRunning 0 "Off" 1 "On" ;
VAL_ 391 GearPosition 2 "Park" 3 "Reverse" 4 "Neutral" 5 "Drive" 6 "B_mode" ;
VAL_ 1428 ChargeType 0 "None" 1 "AC_Type2" 2 "DC_CCS" 3 "CableConnected_NotCharging" ;
VAL_ 1428 ChargePort 0 "No_cable" 1 "Connected" 2 "Connected" 3 "Connected" ;
VAL_ 1428 ChargeTimerMode 0 "Inactive" 1 "Active" 2 "Unknown_2" 3 "Unknown_3" ;
VAL_ 1428 ChargeInProgress 0 "Idle" 1 "Charging" ;
VAL_ 1411 Locked 0 "Unlocked" 1 "Locked" ;
VAL_ 1411 DoorFL 0 "Closed" 1 "Open" ;
VAL_ 1411 DoorFR 0 "Closed" 1 "Open" ;
VAL_ 1411 DoorRL 0 "Closed" 1 "Open" ;
VAL_ 1411 DoorRR 0 "Closed" 1 "Open" ;
VAL_ 1411 DoorTrunk 0 "Closed" 1 "Open" ;
VAL_ 1626 HoodOpen 0 "Closed" 1 "Open" ;
VAL_ 1447 MirrorFold 0 "Idle" 1 "Fold_requested" ;
VAL_ 1447 Horn 0 "Idle" 1 "Horn_requested" ;
VAL_ 1447 Lock 0 "Idle" 1 "Lock_requested" ;
VAL_ 1447 Unlock 0 "Idle" 1 "Unlock_requested" ;
VAL_ 1447 Indicators 0 "Idle" 1 "Flash_requested" ;
VAL_ 1447 Panic 0 "Idle" 1 "Panic_requested" ;
VAL_ 1514 ClimaRemoteMode 0 "Deenergized" 1 "Energized" ;
